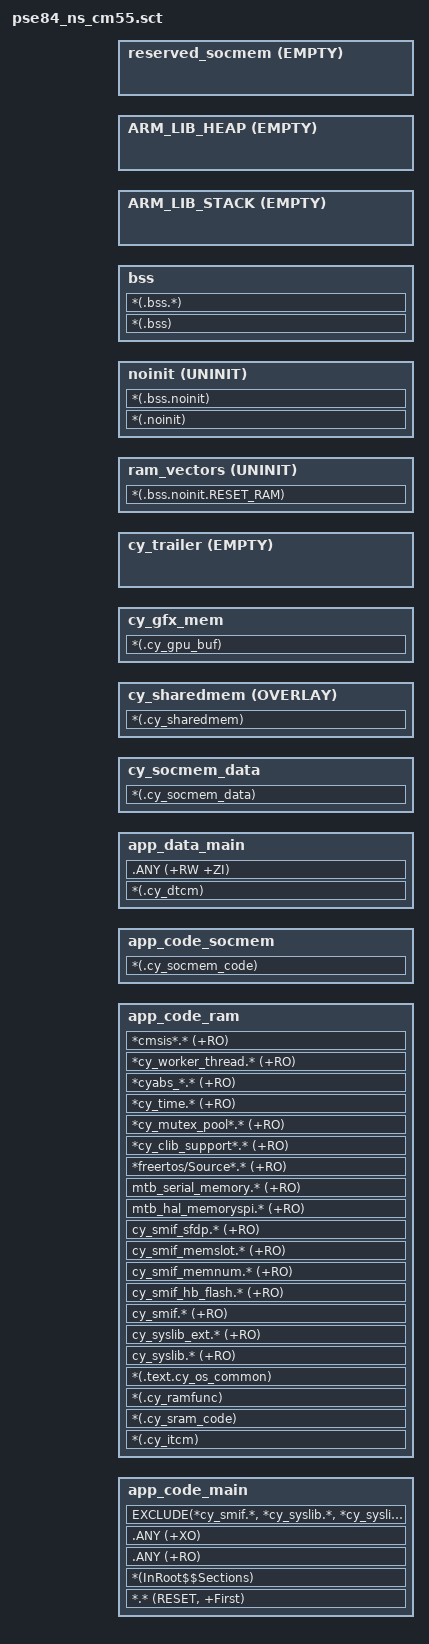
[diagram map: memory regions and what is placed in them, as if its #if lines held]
#! armclang -E --target=arm-arm-none-eabi -mcpu=cortex-m55 -xc
; command above MUST be in first line (no comment above!)
/***************************************************************************//**
* \file pse84_ns_cm55.sct
* \version 1.0.0
*
* scatter file for the armclang C compiler.
*
* The main purpose of this file is to describe how the sections in the
* input files should be mapped into the output file, and to control the memory
* layout of the output file.
*
*
* \note The linker files included with the PDL template projects must be
* generic and handle all common use cases. Your project may not use every
* section defined in the linker files. In that case you may see the warnings
* during the build process: L6314W (no section matches pattern) and/or L6329W
* (pattern only matches removed unused sections). In your project, you can
* suppress the warning by passing the "--diag_suppress=L6314W,L6329W" option to
* the linker, simply comment out or remove the relevant code in the linker
* file.
*
********************************************************************************
* \copyright
* Copyright (c) (2020-2025), Cypress Semiconductor Corporation (an Infineon company) or
* an affiliate of Cypress Semiconductor Corporation.
* SPDX-License-Identifier: Apache-2.0
*
* Licensed under the Apache License, Version 2.0 (the "License");
* you may not use this file except in compliance with the License.
* You may obtain a copy of the License at
*
*     http://www.apache.org/licenses/LICENSE-2.0
*
* Unless required by applicable law or agreed to in writing, software
* distributed under the License is distributed on an "AS IS" BASIS,
* WITHOUT WARRANTIES OR CONDITIONS OF ANY KIND, either express or implied.
* See the License for the specific language governing permissions and
* limitations under the License.
*******************************************************************************/

/* Include the device memory definitions generated by the Device Configurator */
#include "../../config/GeneratedSource/cymem_armlink_CM55_0.sct"

/* Define the stack size for the application */
/* To set stack size in application add makefile ldflags: --predefine="-DAPP_MSP_STACK_SIZE=<CUSTOM_VALUE>" */
#ifdef APP_MSP_STACK_SIZE
#define __STACK_SIZE    APP_MSP_STACK_SIZE
#else
#define __STACK_SIZE    0x0001000
#endif

/* User Stack & Heap boundary definition */
/* Place the top of the stack at the end of the DTCM */
#define __STACK_TOP    (CYMEM_CM55_0_m55_data_INTERNAL_START + CYMEM_CM55_0_m55_data_SIZE)
/* Position the beginning of the heap right after the cy_socmem_data execution region, ensuring an 8-byte alignment */
#define __HEAP_BASE    AlignExpr(ImageLimit(cy_socmem_data), 8)
/* The heap extends to the end of SoCMEM */
#define __HEAP_SIZE   (CYMEM_CM55_0_m55_data_secondary_START + CYMEM_CM55_0_m55_data_secondary_SIZE - __HEAP_BASE)

/* Device definitions */
#define VECTORS_ALIGNMENT 0x400

/* The size of the MCU boot header area at the start of main code region */
#define MCUBOOT_HEADER_SIZE  0x400

/* Serial Memory Interface block #0 memory #1, 16 MB */
/* Start address is offset by MCUBOOT_HEADER_SIZE to let the area free for the MCU boot header */
LR_XIP_PORT0 (CYMEM_CM55_0_m55_nvm_sel_START + MCUBOOT_HEADER_SIZE) (CYMEM_CM55_0_m55_nvm_SIZE - MCUBOOT_HEADER_SIZE)
{
  /* The execution region is designated for the main application code for the Cortex-M55 */
  /* Performance-sensitive or critical functions that need to be executed in sram are manually excluded */
  app_code_main (CYMEM_CM55_0_m55_nvm_sel_START + MCUBOOT_HEADER_SIZE) ALIGN VECTORS_ALIGNMENT (CYMEM_CM55_0_m55_nvm_SIZE - MCUBOOT_HEADER_SIZE)
  {
    *.* (RESET, +First)
    *(InRoot$$Sections)
    .ANY (+RO)
    .ANY (+XO)
    EXCLUDE(*cy_smif.*, *cy_syslib.*, *cy_syslib_ext.*, *cy_smif_memnum.*, *cy_smif_memslot.*, *cy_smif_sfdp.*, *cy_smif_hb_flash.*, *mtb_hal_memoryspi.*, *mtb_serial_memory.*, *freertos/Source*.*, *cy_clib_support*.*, *cy_mutex_pool*.*, *cy_time.*, *cyabs_*.*, *cy_worker_thread.*, *cmsis*.*)
  }

  /* The execution region for performance-sensitive or critical functions that need to be executed in SRAM */
  /* Reserving the first 16 bytes to avoid debug symbols (that have default address 0x0) to be confused with actual code */
  app_code_ram (CYMEM_CM55_0_m55_code_INTERNAL_START + 16) (CYMEM_CM55_0_m55_code_SIZE - 16)
  {
    *(.cy_itcm)
    *(.cy_sram_code)
    *(.cy_ramfunc)
    *(.text.cy_os_common)
    cy_syslib.* (+RO)
    cy_syslib_ext.* (+RO)
    cy_smif.* (+RO)
    cy_smif_hb_flash.* (+RO)
    cy_smif_memnum.* (+RO)
    cy_smif_memslot.* (+RO)
    cy_smif_sfdp.* (+RO)
    mtb_hal_memoryspi.* (+RO)
    mtb_serial_memory.* (+RO)
    *freertos/Source*.* (+RO)
    *cy_clib_support*.* (+RO)
    *cy_mutex_pool*.* (+RO)
    *cy_time.* (+RO)
    *cyabs_*.* (+RO)
    *cy_worker_thread.* (+RO)
    *cmsis*.* (+RO)
  }

  /* The execution region for less performance-sensitive or critical functions that might be executed in SOC memory */
  app_code_socmem CYMEM_CM55_0_m55_code_secondary_START CYMEM_CM55_0_m55_code_secondary_SIZE
  {
    *(.cy_socmem_code)
  }

  /* A region for initialized data memory */
  app_data_main CYMEM_CM55_0_m55_data_INTERNAL_START CYMEM_CM55_0_m55_data_SIZE
  {
    *(.cy_dtcm)
    .ANY (+RW +ZI)
  }

  /* A section for initialized data in SOC memory */
  cy_socmem_data CYMEM_CM55_0_m55_data_secondary_START CYMEM_CM55_0_m55_data_secondary_SIZE
  {
    *(.cy_socmem_data)
  }

  /* A region for shared RAM memory where only the Cortex-M55 can allocate data but all cores can access*/
  cy_sharedmem CYMEM_CM55_0_m55_allocatable_shared_START OVERLAY CYMEM_CM55_0_m55_allocatable_shared_SIZE
  {
    *(.cy_sharedmem)
  }

  /* A region for the GPU buffer */
  cy_gfx_mem CYMEM_CM55_0_gfx_mem_START CYMEM_CM55_0_gfx_mem_SIZE
  {
    *(.cy_gpu_buf)
  }

  /* A reserved region for the trail space for the signature used by the bootloader - do not place any code here */
  cy_trailer (CYMEM_CM55_0_m55_trailer_sel_START) EMPTY CYMEM_CM55_0_m55_trailer_SIZE
  {
  }

}

/* ITCM, 256 KB */
/* Note. This load region must not contain any loadable data; only UNINIT or BSS execution regions are allowed */
LR_ITCM CYMEM_CM55_0_m55_code_INTERNAL_START CYMEM_CM55_0_m55_code_SIZE
{
  /* A region for the vector table */
  ram_vectors AlignExpr(ImageLimit(app_code_ram), VECTORS_ALIGNMENT) ALIGN VECTORS_ALIGNMENT UNINIT (CYMEM_CM55_0_m55_code_SIZE - AlignExpr(ImageLength(app_code_ram), VECTORS_ALIGNMENT))
  {
    *(.bss.noinit.RESET_RAM)
  }
}

/* DTCM, 256 KB */
/* Note. This load region must not contain any loadable data; only UNINIT or BSS execution regions are allowed */
LR_DTCM CYMEM_CM55_0_m55_data_INTERNAL_START CYMEM_CM55_0_m55_data_SIZE
{
  /* A region for variables that should not be initialized during the device startup */
  noinit AlignExpr(ImageLimit(app_data_main), 8) ALIGN 8 UNINIT (CYMEM_CM55_0_m55_data_SIZE - AlignExpr(ImageLength(app_data_main), 8))
  {
    *(.noinit)
    *(.bss.noinit)
  }

  /* A section for non-initialized data memory */
  bss +0 ALIGN 8 (CYMEM_CM55_0_m55_data_SIZE - AlignExpr(ImageLength(app_data_main), 8) - AlignExpr(ImageLength(noinit), 8))
  {
    *(.bss)
    *(.bss.*)
  }

  /* A region for stack */
  ARM_LIB_STACK __STACK_TOP EMPTY -__STACK_SIZE
  {
  }
}

/* System SRAM (SoCMEM), 5MB */
/* Note. This load region must not contain any loadable data; only UNINIT or BSS execution regions are allowed */
LR_SOCMEM CYMEM_CM55_0_m55_code_secondary_START (CYMEM_CM55_0_m55_code_secondary_SIZE + CYMEM_CM55_0_m33_m55_shared_SIZE + CYMEM_CM55_0_gfx_mem_SIZE + CYMEM_CM55_0_m55_data_secondary_SIZE)
{
  /* A region for the heap memory */
  ARM_LIB_HEAP __HEAP_BASE EMPTY __HEAP_SIZE
  {
  }

  /* A region for reserved SOC memory */
  reserved_socmem CYMEM_CM55_0_m33_m55_shared_START EMPTY CYMEM_CM55_0_m33_m55_shared_SIZE
  {
  }

}
